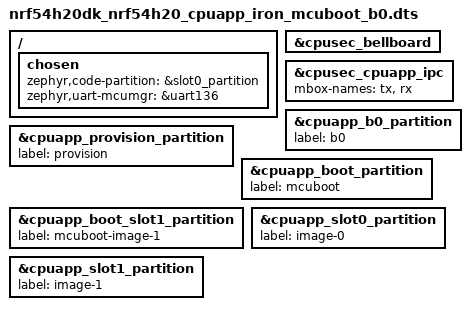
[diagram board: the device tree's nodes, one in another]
/*
 * Copyright (c) 2025 Nordic Semiconductor ASA
 *
 * SPDX-License-Identifier: Apache-2.0
 */

#include "nrf54h20dk_nrf54h20_cpuapp.dts"
#include "nrf54h20dk_nrf54h20-ipc_conf_iron.dtsi"
#include "nrf54h20dk_nrf54h20-memory_map_iron_mcuboot_b0.dtsi"

/delete-node/ &cpusec_cpurad_ipc;

/ {
	chosen {
		zephyr,code-partition = &slot0_partition;
		zephyr,uart-mcumgr = &uart136;
	};
};

&cpusec_bellboard {
	status = "okay";
};

&cpusec_cpuapp_ipc {
	mbox-names = "tx", "rx";
	status = "okay";
};

b0_partition: &cpuapp_b0_partition {
	label = "b0";
};

provision_partition: &cpuapp_provision_partition {
	label = "provision";
};

boot_partition: &cpuapp_boot_partition {
	label = "mcuboot";
};

boot_partition_slot1: &cpuapp_boot_slot1_partition {
	label = "mcuboot-image-1";
};

slot0_partition: &cpuapp_slot0_partition {
	label = "image-0";
};

slot1_partition: &cpuapp_slot1_partition {
	label = "image-1";
};
